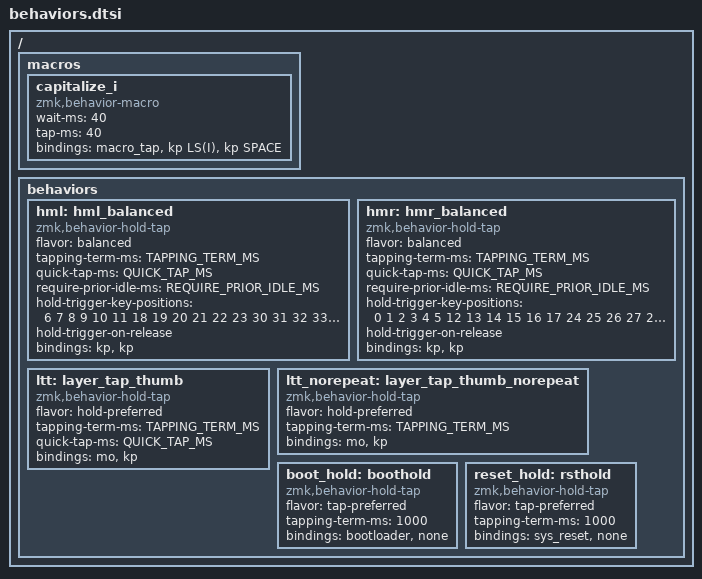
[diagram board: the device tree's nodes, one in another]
/ {
    macros {
        capitalize_i: capitalize_i {
            compatible = "zmk,behavior-macro";
            #binding-cells = <0>;
            wait-ms = <40>;
            tap-ms = <40>;
            bindings = <&macro_tap &kp LS(I) &kp SPACE>;
        };
    };

    behaviors {
        // Home Row Mods
        // See: https://zmk.dev/docs/keymaps/behaviors/hold-tap?examples=home_row_mods#custom-hold-tap-examples
        hml: hml_balanced {
            compatible = "zmk,behavior-hold-tap";
            #binding-cells = <2>;
            flavor = "balanced";
            tapping-term-ms = <TAPPING_TERM_MS>;
            quick-tap-ms = <QUICK_TAP_MS>;
            require-prior-idle-ms = <REQUIRE_PRIOR_IDLE_MS>;
            hold-trigger-key-positions = <6 7 8 9 10 11 18 19 20 21 22 23 30 31 32 33 34 35 39 40 41>;
            hold-trigger-on-release;
            bindings = <&kp>, <&kp>;
        };

        hmr: hmr_balanced {
            compatible = "zmk,behavior-hold-tap";
            #binding-cells = <2>;
            flavor = "balanced";
            tapping-term-ms = <TAPPING_TERM_MS>;
            quick-tap-ms = <QUICK_TAP_MS>;
            require-prior-idle-ms = <REQUIRE_PRIOR_IDLE_MS>;
            hold-trigger-key-positions = <0 1 2 3 4 5 12 13 14 15 16 17 24 25 26 27 28 29 36 37 38>;
            hold-trigger-on-release;
            bindings = <&kp>, <&kp>;
        };

        // Thumb layer-tap with auto-repeat (Num thumb)
        ltt: layer_tap_thumb {
            compatible = "zmk,behavior-hold-tap";
            #binding-cells = <2>;
            flavor = "hold-preferred";
            tapping-term-ms = <TAPPING_TERM_MS>;
            quick-tap-ms = <QUICK_TAP_MS>;
            bindings = <&mo>, <&kp>;
        };

        // Thumb layer-tap without auto-repeat (Nav thumb)
        ltt_norepeat: layer_tap_thumb_norepeat {
            compatible = "zmk,behavior-hold-tap";
            #binding-cells = <2>;
            flavor = "hold-preferred";
            tapping-term-ms = <TAPPING_TERM_MS>;
            bindings = <&mo>, <&kp>;
        };

        // 1-second hold-to-activate wrappers for bootloader & reset
        boot_hold: boothold {
            compatible = "zmk,behavior-hold-tap";
            #binding-cells = <2>;
            flavor = "tap-preferred";
            tapping-term-ms = <1000>;
            bindings = <&bootloader>, <&none>;
        };

        reset_hold: rsthold {
            compatible = "zmk,behavior-hold-tap";
            #binding-cells = <2>;
            flavor = "tap-preferred";
            tapping-term-ms = <1000>;
            bindings = <&sys_reset>, <&none>;
        };
    };
};
